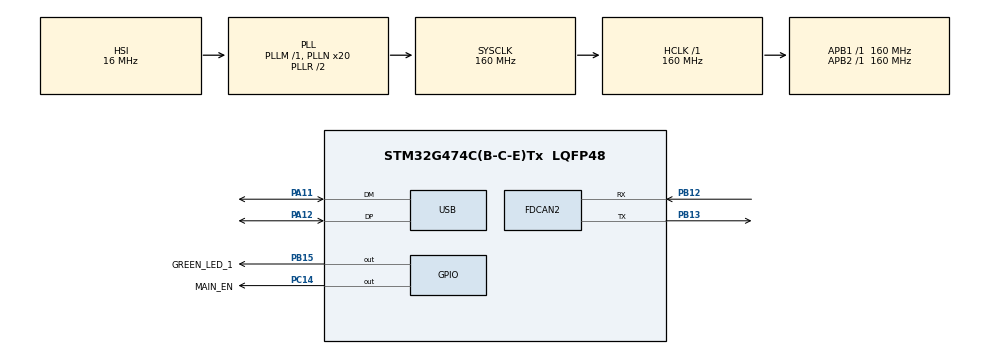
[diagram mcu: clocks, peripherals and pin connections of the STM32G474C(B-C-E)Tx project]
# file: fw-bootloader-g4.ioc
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FDCAN2.AutoRetransmission=ENABLE
FDCAN2.CalculateBaudRateNominal=250000
FDCAN2.CalculateTimeBitNominal=4000
FDCAN2.CalculateTimeQuantumNominal=200.0
FDCAN2.DataPrescaler=32
FDCAN2.DataSyncJumpWidth=4
FDCAN2.DataTimeSeg1=15
FDCAN2.DataTimeSeg2=4
FDCAN2.ExtFiltersNbr=4
FDCAN2.NominalPrescaler=32
FDCAN2.NominalSyncJumpWidth=4
FDCAN2.NominalTimeSeg1=15
FDCAN2.NominalTimeSeg2=4
FDCAN2.TxFifoQueueMode=FDCAN_TX_QUEUE_OPERATION
Mcu.Family=STM32G4
Mcu.Name=STM32G474C(B-C-E)Tx
Mcu.Package=LQFP48
NVIC.FDCAN2_IT0_IRQn=true\:0\:0\:false\:false\:true\:true\:true\:true
NVIC.FDCAN2_IT1_IRQn=true\:0\:0\:false\:false\:true\:true\:true\:true
NVIC.PriorityGroup=NVIC_PRIORITYGROUP_4
NVIC.TIM1_BRK_TIM15_IRQn=true\:0\:0\:false\:false\:true\:true\:true\:true
NVIC.TIM2_IRQn=true\:0\:0\:false\:false\:true\:true\:true\:true
NVIC.TIM3_IRQn=true\:0\:0\:false\:false\:true\:true\:true\:true
NVIC.USB_LP_IRQn=true\:0\:0\:false\:false\:true\:false\:true\:true
PA11.Mode=Device
PA11.Signal=USB_DM
PA12.Mode=Device
PA12.Signal=USB_DP
PA13.Mode=Serial_Wire
PA13.Signal=SYS_JTMS-SWDIO
PA14.Mode=Serial_Wire
PA14.Signal=SYS_JTCK-SWCLK
PB12.Mode=FDCAN_Activate
PB12.Signal=FDCAN2_RX
PB13.Mode=FDCAN_Activate
PB13.Signal=FDCAN2_TX
PB15.GPIO_Label=GREEN_LED_1
PB15.Signal=GPIO_Output
PC14-OSC32_IN.GPIO_Label=MAIN_EN
PC14-OSC32_IN.Signal=GPIO_Output
PF0-OSC_IN.Mode=HSE-External-Clock-Source
PF0-OSC_IN.Signal=RCC_OSC_IN
ProjectManager.HeapSize=0x200
ProjectManager.StackSize=0x400
ProjectManager.TargetToolchain=STM32CubeIDE
RCC.ADC12Freq_Value=160000000
RCC.ADC345Freq_Value=160000000
RCC.AHBFreq_Value=160000000
RCC.APB1Freq_Value=160000000
RCC.APB1TimFreq_Value=160000000
RCC.APB2Freq_Value=160000000
RCC.APB2TimFreq_Value=160000000
RCC.CK48CLockSelection=RCC_USBCLKSOURCE_HSI48
RCC.CortexFreq_Value=160000000
RCC.EXTERNAL_CLOCK_VALUE=12288000
RCC.HCLKFreq_Value=160000000
RCC.HSE_VALUE=8000000
RCC.HSI48_VALUE=48000000
RCC.HSI_VALUE=16000000
RCC.LSE_VALUE=32768
RCC.PLLN=20
RCC.PLLQ=RCC_PLLQ_DIV6
RCC.SYSCLKFreq_VALUE=160000000
RCC.SYSCLKSource=RCC_SYSCLKSOURCE_PLLCLK
RCC.USBFreq_Value=48000000
RCC.VCOOutputFreq_Value=320000000
USB_DEVICE.CLASS_NAME_FS=CDC
USB_DEVICE.VirtualMode=Cdc
USB_DEVICE.VirtualModeFS=Cdc_FS
VP_SYS_VS_DBSignals.Mode=DisableDeadBatterySignals
VP_TIM1_VS_ClockSourceINT.Mode=Internal
VP_TIM2_VS_ClockSourceINT.Mode=Internal
VP_TIM3_VS_ClockSourceINT.Mode=Internal
VP_USB_DEVICE_VS_USB_DEVICE_CDC_FS.Mode=CDC_FS
board=custom

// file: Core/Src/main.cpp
/* USER CODE BEGIN Header */
/**
  ******************************************************************************
  * @file           : main.c
  * @brief          : Main program body
  ******************************************************************************
  * @attention
  *
  * Copyright (c) 2025 STMicroelectronics.
  * All rights reserved.
  *
  * This software is licensed under terms that can be found in the LICENSE file
  * in the root directory of this software component.
  * If no LICENSE file comes with this software, it is provided AS-IS.
  *
  ******************************************************************************
  */
/* USER CODE END Header */
#include "main.h"
#include "usb_device.h"

/* USER CODE BEGIN Includes */
#include "bootloader_main.hpp"
/* USER CODE END Includes */

FDCAN_HandleTypeDef hfdcan2;

TIM_HandleTypeDef htim1;
TIM_HandleTypeDef htim2;
TIM_HandleTypeDef htim3;

/* USER CODE BEGIN PV */
uint8_t timer_1_flag = 0;

/* USER CODE END PV */

void SystemClock_Config(void);
static void MX_GPIO_Init(void);
static void MX_FDCAN2_Init(void);
static void MX_TIM1_Init(void);
static void MX_TIM2_Init(void);
static void MX_TIM3_Init(void);

int main(void)
{

  /* MCU Configuration--------------------------------------------------------*/

  /* Reset of all peripherals, Initializes the Flash interface and the Systick. */
  HAL_Init();

  /* Configure the system clock */
  SystemClock_Config();

  /* Initialize all configured peripherals */
  MX_GPIO_Init();
  MX_FDCAN2_Init();
  MX_TIM1_Init();
  MX_TIM2_Init();
  MX_TIM3_Init();
  MX_USB_Device_Init();

  /* Infinite loop */
  /* USER CODE BEGIN WHILE */
  bootloaderMain(&hfdcan2, &htim1);
  while (1)
  {
    /* USER CODE END WHILE */

  }
}

void SystemClock_Config(void)
{
  RCC_OscInitTypeDef RCC_OscInitStruct = {0};
  RCC_ClkInitTypeDef RCC_ClkInitStruct = {0};

  /** Configure the main internal regulator output voltage
  */
  HAL_PWREx_ControlVoltageScaling(PWR_REGULATOR_VOLTAGE_SCALE1_BOOST);

  /** Initializes the RCC Oscillators according to the specified parameters
  * in the RCC_OscInitTypeDef structure.
  */
  RCC_OscInitStruct.OscillatorType = RCC_OSCILLATORTYPE_HSI|RCC_OSCILLATORTYPE_HSI48;
  RCC_OscInitStruct.HSIState = RCC_HSI_ON;
  RCC_OscInitStruct.HSICalibrationValue = RCC_HSICALIBRATION_DEFAULT;
  RCC_OscInitStruct.HSI48State = RCC_HSI48_ON;
  RCC_OscInitStruct.PLL.PLLState = RCC_PLL_ON;
  RCC_OscInitStruct.PLL.PLLSource = RCC_PLLSOURCE_HSI;
  RCC_OscInitStruct.PLL.PLLM = RCC_PLLM_DIV1;
  RCC_OscInitStruct.PLL.PLLN = 20;
  RCC_OscInitStruct.PLL.PLLP = RCC_PLLP_DIV2;
  RCC_OscInitStruct.PLL.PLLQ = RCC_PLLQ_DIV6;
  RCC_OscInitStruct.PLL.PLLR = RCC_PLLR_DIV2;
  if (HAL_RCC_OscConfig(&RCC_OscInitStruct) != HAL_OK)
  {
    Error_Handler();
  }

  /** Initializes the CPU, AHB and APB buses clocks
  */
  RCC_ClkInitStruct.ClockType = RCC_CLOCKTYPE_HCLK|RCC_CLOCKTYPE_SYSCLK
                              |RCC_CLOCKTYPE_PCLK1|RCC_CLOCKTYPE_PCLK2;
  RCC_ClkInitStruct.SYSCLKSource = RCC_SYSCLKSOURCE_PLLCLK;
  RCC_ClkInitStruct.AHBCLKDivider = RCC_SYSCLK_DIV1;
  RCC_ClkInitStruct.APB1CLKDivider = RCC_HCLK_DIV1;
  RCC_ClkInitStruct.APB2CLKDivider = RCC_HCLK_DIV1;

  if (HAL_RCC_ClockConfig(&RCC_ClkInitStruct, FLASH_LATENCY_4) != HAL_OK)
  {
    Error_Handler();
  }
}

static void MX_FDCAN2_Init(void)
{

  hfdcan2.Instance = FDCAN2;
  hfdcan2.Init.ClockDivider = FDCAN_CLOCK_DIV1;
  hfdcan2.Init.FrameFormat = FDCAN_FRAME_CLASSIC;
  hfdcan2.Init.Mode = FDCAN_MODE_NORMAL;
  hfdcan2.Init.AutoRetransmission = ENABLE;
  hfdcan2.Init.TransmitPause = DISABLE;
  hfdcan2.Init.ProtocolException = DISABLE;
  hfdcan2.Init.NominalPrescaler = 32;
  hfdcan2.Init.NominalSyncJumpWidth = 4;
  hfdcan2.Init.NominalTimeSeg1 = 15;
  hfdcan2.Init.NominalTimeSeg2 = 4;
  hfdcan2.Init.DataPrescaler = 32;
  hfdcan2.Init.DataSyncJumpWidth = 4;
  hfdcan2.Init.DataTimeSeg1 = 15;
  hfdcan2.Init.DataTimeSeg2 = 4;
  hfdcan2.Init.StdFiltersNbr = 0;
  hfdcan2.Init.ExtFiltersNbr = 4;
  hfdcan2.Init.TxFifoQueueMode = FDCAN_TX_QUEUE_OPERATION;
  if (HAL_FDCAN_Init(&hfdcan2) != HAL_OK)
  {
    Error_Handler();
  }

}

static void MX_TIM1_Init(void)
{

  TIM_ClockConfigTypeDef sClockSourceConfig = {0};
  TIM_MasterConfigTypeDef sMasterConfig = {0};

  htim1.Instance = TIM1;
  htim1.Init.Prescaler = 0;
  htim1.Init.CounterMode = TIM_COUNTERMODE_UP;
  htim1.Init.Period = 65535;
  htim1.Init.ClockDivision = TIM_CLOCKDIVISION_DIV1;
  htim1.Init.RepetitionCounter = 0;
  htim1.Init.AutoReloadPreload = TIM_AUTORELOAD_PRELOAD_DISABLE;
  if (HAL_TIM_Base_Init(&htim1) != HAL_OK)
  {
    Error_Handler();
  }
  sClockSourceConfig.ClockSource = TIM_CLOCKSOURCE_INTERNAL;
  if (HAL_TIM_ConfigClockSource(&htim1, &sClockSourceConfig) != HAL_OK)
  {
    Error_Handler();
  }
  sMasterConfig.MasterOutputTrigger = TIM_TRGO_RESET;
  sMasterConfig.MasterOutputTrigger2 = TIM_TRGO2_RESET;
  sMasterConfig.MasterSlaveMode = TIM_MASTERSLAVEMODE_DISABLE;
  if (HAL_TIMEx_MasterConfigSynchronization(&htim1, &sMasterConfig) != HAL_OK)
  {
    Error_Handler();
  }

}

static void MX_TIM2_Init(void)
{

  TIM_ClockConfigTypeDef sClockSourceConfig = {0};
  TIM_MasterConfigTypeDef sMasterConfig = {0};

  htim2.Instance = TIM2;
  htim2.Init.Prescaler = 0;
  htim2.Init.CounterMode = TIM_COUNTERMODE_UP;
  htim2.Init.Period = 4294967295;
  htim2.Init.ClockDivision = TIM_CLOCKDIVISION_DIV1;
  htim2.Init.AutoReloadPreload = TIM_AUTORELOAD_PRELOAD_DISABLE;
  if (HAL_TIM_Base_Init(&htim2) != HAL_OK)
  {
    Error_Handler();
  }
  sClockSourceConfig.ClockSource = TIM_CLOCKSOURCE_INTERNAL;
  if (HAL_TIM_ConfigClockSource(&htim2, &sClockSourceConfig) != HAL_OK)
  {
    Error_Handler();
  }
  sMasterConfig.MasterOutputTrigger = TIM_TRGO_RESET;
  sMasterConfig.MasterSlaveMode = TIM_MASTERSLAVEMODE_DISABLE;
  if (HAL_TIMEx_MasterConfigSynchronization(&htim2, &sMasterConfig) != HAL_OK)
  {
    Error_Handler();
  }

}

static void MX_TIM3_Init(void)
{

  TIM_ClockConfigTypeDef sClockSourceConfig = {0};
  TIM_MasterConfigTypeDef sMasterConfig = {0};

  htim3.Instance = TIM3;
  htim3.Init.Prescaler = 0;
  htim3.Init.CounterMode = TIM_COUNTERMODE_UP;
  htim3.Init.Period = 65535;
  htim3.Init.ClockDivision = TIM_CLOCKDIVISION_DIV1;
  htim3.Init.AutoReloadPreload = TIM_AUTORELOAD_PRELOAD_DISABLE;
  if (HAL_TIM_Base_Init(&htim3) != HAL_OK)
  {
    Error_Handler();
  }
  sClockSourceConfig.ClockSource = TIM_CLOCKSOURCE_INTERNAL;
  if (HAL_TIM_ConfigClockSource(&htim3, &sClockSourceConfig) != HAL_OK)
  {
    Error_Handler();
  }
  sMasterConfig.MasterOutputTrigger = TIM_TRGO_RESET;
  sMasterConfig.MasterSlaveMode = TIM_MASTERSLAVEMODE_DISABLE;
  if (HAL_TIMEx_MasterConfigSynchronization(&htim3, &sMasterConfig) != HAL_OK)
  {
    Error_Handler();
  }

}

static void MX_GPIO_Init(void)
{
  GPIO_InitTypeDef GPIO_InitStruct = {0};

  /* GPIO Ports Clock Enable */
  __HAL_RCC_GPIOC_CLK_ENABLE();
  __HAL_RCC_GPIOF_CLK_ENABLE();
  __HAL_RCC_GPIOB_CLK_ENABLE();
  __HAL_RCC_GPIOA_CLK_ENABLE();

  /*Configure GPIO pin Output Level */
  HAL_GPIO_WritePin(MAIN_EN_GPIO_Port, MAIN_EN_Pin, GPIO_PIN_RESET);

  /*Configure GPIO pin Output Level */
  HAL_GPIO_WritePin(GREEN_LED_1_GPIO_Port, GREEN_LED_1_Pin, GPIO_PIN_RESET);

  /*Configure GPIO pin : MAIN_EN_Pin */
  GPIO_InitStruct.Pin = MAIN_EN_Pin;
  GPIO_InitStruct.Mode = GPIO_MODE_OUTPUT_PP;
  GPIO_InitStruct.Pull = GPIO_NOPULL;
  GPIO_InitStruct.Speed = GPIO_SPEED_FREQ_LOW;
  HAL_GPIO_Init(MAIN_EN_GPIO_Port, &GPIO_InitStruct);

  /*Configure GPIO pin : GREEN_LED_1_Pin */
  GPIO_InitStruct.Pin = GREEN_LED_1_Pin;
  GPIO_InitStruct.Mode = GPIO_MODE_OUTPUT_PP;
  GPIO_InitStruct.Pull = GPIO_NOPULL;
  GPIO_InitStruct.Speed = GPIO_SPEED_FREQ_LOW;
  HAL_GPIO_Init(GREEN_LED_1_GPIO_Port, &GPIO_InitStruct);

}

void Error_Handler(void)
{
  __disable_irq();
  while (1)
  {
  }
}
